AUTOSAR XML (schema 00046)
package /ASWComponent
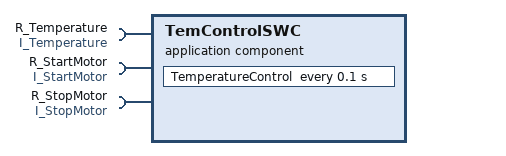
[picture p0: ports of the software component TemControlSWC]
  application sw component type TemControlSWC
    require port R_Temperature: required-interface=I_Temperature
    require port R_StartMotor: required-interface=I_StartMotor
    require port R_StopMotor: required-interface=I_StopMotor
    behavior IB_SWC
      timing event TE_10ms: start-on-event=TemperatureControl, period=0.1
      runnable TemperatureControl: symbol=ApplTemperatureControl
        data-receive-point-by-arguments:
          access VA_Temp: accessed-variable=R_Temperature.Temperature
        sync call SC_StartMotor: operation=R_StartMotor.StartMotor
        sync call SC_StopMotor: operation=R_StopMotor.StopMotor
